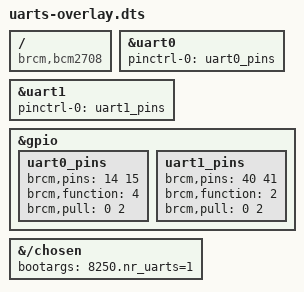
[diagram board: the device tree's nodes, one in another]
/dts-v1/;
/plugin/;

/{
    compatible = "brcm,bcm2708";

    fragment@0 {
        target = <&uart0>;
        __overlay__ {
            pinctrl-names = "default";
            pinctrl-0 = <&uart0_pins>;
            status = "okay";
        };
    };

    fragment@1 {
        target = <&uart1>;
        __overlay__ {
            pinctrl-names = "default";
            pinctrl-0 = <&uart1_pins>;
            status = "okay";
        };
    };

    fragment@2 {
        target = <&gpio>;
        __overlay__ {
            uart0_pins: uart0_pins {
                brcm,pins = <14 15>; /* UART0: TXD0 RXD0 */
                brcm,function = <4>; /* alt0 */
                brcm,pull = <0 2>;
            };
        };
    };

    fragment@3 {
        target = <&gpio>;
        __overlay__ {
            uart1_pins: uart1_pins {
                brcm,pins = <40 41>; /* UART1: TX1 RX1 */
                brcm,function = <2>; /* alt5 */
                brcm,pull = <0 2>;
            };
        };
    };

    fragment@4 {
        target-path = "/chosen";
        __overlay__ {
            bootargs = "8250.nr_uarts=1";
        };
    };

    __overrides__ {
        txd0_pin = <&uart0_pins>,"brcm,pins:0";
        rxd0_pin = <&uart0_pins>,"brcm,pins:4";
        txd1_pin = <&uart1_pins>,"brcm,pins:0";
        rxd1_pin = <&uart1_pins>,"brcm,pins:4";
    };
};
